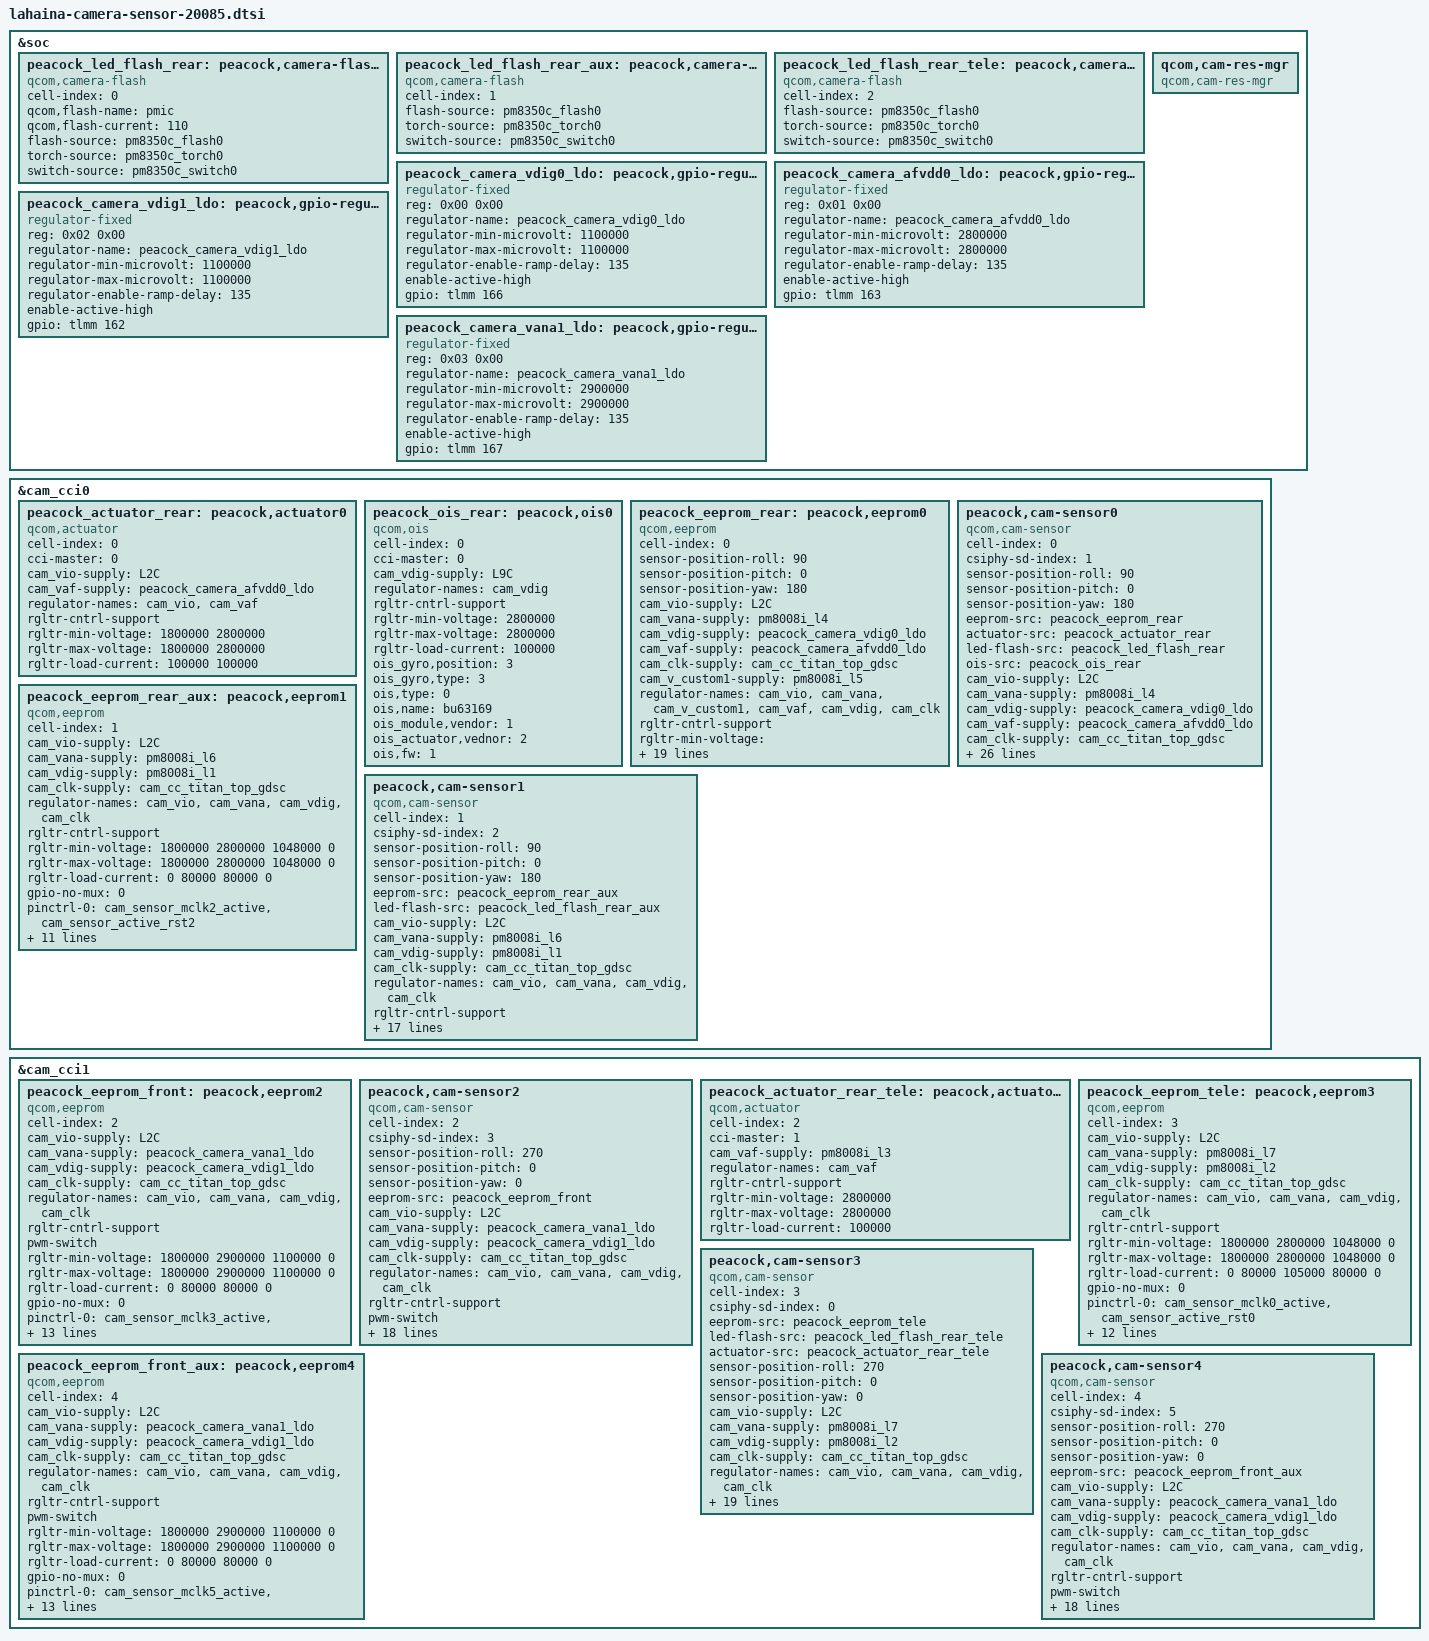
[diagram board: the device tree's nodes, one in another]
#include <dt-bindings/clock/qcom,camcc-lahaina.h>
&soc {
    peacock_led_flash_rear: peacock,camera-flash0 {
        cell-index = <0>;
        compatible = "qcom,camera-flash";
        qcom,flash-name = "pmic";
        qcom,flash-current = <110>;
        flash-source = <&pm8350c_flash0>;
        torch-source = <&pm8350c_torch0>;
        switch-source = <&pm8350c_switch0>;
        status = "ok";
    };

    peacock_led_flash_rear_aux: peacock,camera-flash1 {
        cell-index = <1>;
        compatible = "qcom,camera-flash";
        flash-source = <&pm8350c_flash0>;
        torch-source = <&pm8350c_torch0>;
        switch-source = <&pm8350c_switch0>;
        status = "ok";
    };

    peacock_led_flash_rear_tele: peacock,camera-flash2 {
        cell-index = <2>;
        compatible = "qcom,camera-flash";
        flash-source = <&pm8350c_flash0>;
        torch-source = <&pm8350c_torch0>;
        switch-source = <&pm8350c_switch0>;
        status = "ok";
    };

    peacock_camera_vdig0_ldo: peacock,gpio-regulator@0 {
        compatible = "regulator-fixed";
        reg = <0x00 0x00>;
        regulator-name = "peacock_camera_vdig0_ldo";
        regulator-min-microvolt = <1100000>;
        regulator-max-microvolt = <1100000>;
        regulator-enable-ramp-delay = <135>;
        enable-active-high;
        gpio = <&tlmm 166 0>;
        pinctrl-names = "default";
    };

    peacock_camera_afvdd0_ldo: peacock,gpio-regulator@1 {
        compatible = "regulator-fixed";
        reg = <0x01 0x00>;
        regulator-name = "peacock_camera_afvdd0_ldo";
        regulator-min-microvolt = <2800000>;
        regulator-max-microvolt = <2800000>;
        regulator-enable-ramp-delay = <135>;
        enable-active-high;
        gpio = <&tlmm 163 0>;
        pinctrl-names = "default";
    };

    peacock_camera_vdig1_ldo: peacock,gpio-regulator@2 {
        compatible = "regulator-fixed";
        reg = <0x02 0x00>;
        regulator-name = "peacock_camera_vdig1_ldo";
        regulator-min-microvolt = <1100000>;
        regulator-max-microvolt = <1100000>;
        regulator-enable-ramp-delay = <135>;
        enable-active-high;
        gpio = <&tlmm 162 0>;
        pinctrl-names = "default";
    };

    peacock_camera_vana1_ldo: peacock,gpio-regulator@3 {
        compatible = "regulator-fixed";
        reg = <0x03 0x00>;
        regulator-name = "peacock_camera_vana1_ldo";
        regulator-min-microvolt = <2900000>;
        regulator-max-microvolt = <2900000>;
        regulator-enable-ramp-delay = <135>;
        enable-active-high;
        gpio = <&tlmm 167 0>;
        pinctrl-names = "default";
    };

    qcom,cam-res-mgr {
        compatible = "qcom,cam-res-mgr";
        status = "ok";
    };
};

&cam_cci0 {
    peacock_actuator_rear: peacock,actuator0 {
        cell-index = <0>;
        compatible = "qcom,actuator";
        cci-master = <0>;
        cam_vio-supply = <&L2C>;
        cam_vaf-supply = <&peacock_camera_afvdd0_ldo>;
        regulator-names = "cam_vio", "cam_vaf";
        rgltr-cntrl-support;
        rgltr-min-voltage = <1800000 2800000>;
        rgltr-max-voltage = <1800000 2800000>;
        rgltr-load-current = <100000 100000>;
    };

    peacock_ois_rear: peacock,ois0 {
        cell-index = <0>;
        compatible = "qcom,ois";
        cci-master = <0>;
        cam_vdig-supply = <&L9C>;
        regulator-names = "cam_vdig";
        rgltr-cntrl-support;
        rgltr-min-voltage = <2800000>;
        rgltr-max-voltage = <2800000>;
        rgltr-load-current = <100000>;
        ois_gyro,position=<3>;
        ois_gyro,type=<3>;
        ois,type=<0>;
        ois,name="bu63169";
        ois_module,vendor=<1>;
        ois_actuator,vednor=<2>;
        ois,fw=<1>;
        status = "ok";
    };
    peacock_eeprom_rear: peacock,eeprom0 {
        cell-index = <0>;
        compatible = "qcom,eeprom";
        sensor-position-roll = <90>;
        sensor-position-pitch = <0>;
        sensor-position-yaw = <180>;
        cam_vio-supply = <&L2C>;
        cam_vana-supply = <&pm8008i_l4>;
        cam_vdig-supply = <&peacock_camera_vdig0_ldo>;
        cam_vaf-supply = <&peacock_camera_afvdd0_ldo>;
        cam_clk-supply = <&cam_cc_titan_top_gdsc>;
        cam_v_custom1-supply = <&pm8008i_l5>;
        regulator-names = "cam_vio", "cam_vana", "cam_v_custom1", "cam_vaf", "cam_vdig",
            "cam_clk";
        rgltr-cntrl-support;
        rgltr-min-voltage = <1800000 2800000 1800000 2800000 1100000 0>;
        rgltr-max-voltage = <1800000 2800000 1800000 2800000 1100000 0>;
        rgltr-load-current = <0 80000 80000 80000 105000 0>;
        gpio-no-mux = <0>;
        pinctrl-names = "cam_default", "cam_suspend";
        pinctrl-0 = <&cam_sensor_mclk1_active
                &cam_sensor_active_rst1>;
        pinctrl-1 = <&cam_sensor_mclk1_suspend
                &cam_sensor_suspend_rst1>;
        gpios = <&tlmm 101 0>,
            <&tlmm 16 0>;
        gpio-reset = <1>;
        gpio-req-tbl-num = <0 1>;
        gpio-req-tbl-flags = <1 0>;
        gpio-req-tbl-label = "CAMIF_MCLK1",
                    "CAM_RESET1";
        cci-master = <0>;
        status = "ok";
        clocks = <&clock_camcc CAM_CC_MCLK1_CLK>;
        clock-names = "cam_clk";
        clock-cntl-level = "nominal";
        clock-rates = <19200000>;
    };

    peacock,cam-sensor0 {
        cell-index = <0>;
        compatible = "qcom,cam-sensor";
        csiphy-sd-index = <1>;
        sensor-position-roll = <90>;
        sensor-position-pitch = <0>;
        sensor-position-yaw = <180>;
        eeprom-src = <&peacock_eeprom_rear>;
        actuator-src = <&peacock_actuator_rear>;
        led-flash-src = <&peacock_led_flash_rear>;
        ois-src = <&peacock_ois_rear>;
        cam_vio-supply = <&L2C>;
        cam_vana-supply = <&pm8008i_l4>;
        cam_vdig-supply = <&peacock_camera_vdig0_ldo>;
        cam_vaf-supply = <&peacock_camera_afvdd0_ldo>;
        cam_clk-supply = <&cam_cc_titan_top_gdsc>;
        cam_v_custom1-supply = <&pm8008i_l5>;
        regulator-names = "cam_vio", "cam_vana", "cam_v_custom1", "cam_vaf", "cam_vdig",
            "cam_clk";
        rgltr-cntrl-support;
        rgltr-min-voltage = <1800000 2800000 1800000 2800000 1100000 0>;
        rgltr-max-voltage = <1800000 2800000 1800000 2800000 1100000 0>;
        rgltr-load-current = <0 80000 80000 80000 105000 0>;
        gpio-no-mux = <0>;
        pinctrl-names = "cam_default", "cam_suspend";
        pinctrl-0 = <&cam_sensor_mclk1_active
                &cam_sensor_active_rst1>;
        pinctrl-1 = <&cam_sensor_mclk1_suspend
                &cam_sensor_suspend_rst1>;
        gpios = <&tlmm 101 0>,
            <&tlmm 16 0>;
        gpio-reset = <1>;
        gpio-req-tbl-num = <0 1>;
        gpio-req-tbl-flags = <1 0>;
        gpio-req-tbl-label = "CAMIF_MCLK1",
                    "CAM_RESET1";
        cci-master = <0>;
        status = "ok";
        clocks = <&clock_camcc CAM_CC_MCLK1_CLK>;
        clock-names = "cam_clk";
        clock-cntl-level = "nominal";
        clock-rates = <19200000>;
        is-read-eeprom = <2>;
        advance-powerup-vendor = <0x85>;
    };

    peacock_eeprom_rear_aux: peacock,eeprom1 {
        cell-index = <1>;
        compatible = "qcom,eeprom";
        cam_vio-supply = <&L2C>;
        cam_vana-supply = <&pm8008i_l6>;
        cam_vdig-supply = <&pm8008i_l1>;
        cam_clk-supply = <&cam_cc_titan_top_gdsc>;
        regulator-names = "cam_vio", "cam_vana", "cam_vdig", "cam_clk";
        rgltr-cntrl-support;
        rgltr-min-voltage = <1800000 2800000 1048000 0>;
        rgltr-max-voltage = <1800000 2800000 1048000 0>;
        rgltr-load-current = <0 80000 80000 0>;
        gpio-no-mux = <0>;
        pinctrl-names = "cam_default", "cam_suspend";
        pinctrl-0 = <&cam_sensor_mclk2_active
                &cam_sensor_active_rst2>;
        pinctrl-1 = <&cam_sensor_mclk2_suspend
                &cam_sensor_suspend_rst2>;
        gpios = <&tlmm 102 0>,
            <&tlmm 106 0>;
        gpio-reset = <1>;
        gpio-req-tbl-num = <0 1>;
        gpio-req-tbl-flags = <1 0>;
        gpio-req-tbl-label = "CAMIF_MCLK2",
                    "CAM_RESET2";
        cci-master = <1>;
        status = "ok";
        clocks = <&clock_camcc CAM_CC_MCLK2_CLK>;
        clock-names = "cam_clk";
        clock-cntl-level = "turbo";
        clock-rates = <19200000>;
    };

    peacock,cam-sensor1 {
        cell-index = <1>;
        compatible = "qcom,cam-sensor";
        csiphy-sd-index = <2>;
        sensor-position-roll = <90>;
        sensor-position-pitch = <0>;
        sensor-position-yaw = <180>;
        eeprom-src = <&peacock_eeprom_rear_aux>;
        led-flash-src = <&peacock_led_flash_rear_aux>;
        cam_vio-supply = <&L2C>;
        cam_vana-supply = <&pm8008i_l6>;
        cam_vdig-supply = <&pm8008i_l1>;
        cam_clk-supply = <&cam_cc_titan_top_gdsc>;
        regulator-names = "cam_vio", "cam_vana", "cam_vdig", "cam_clk";
        rgltr-cntrl-support;
        rgltr-min-voltage = <1800000 2800000 1048000 0>;
        rgltr-max-voltage = <1800000 2800000 1048000 0>;
        rgltr-load-current = <0 80000 80000 0>;
        gpio-no-mux = <0>;
        pinctrl-names = "cam_default", "cam_suspend";
        pinctrl-0 = <&cam_sensor_mclk2_active
                &cam_sensor_active_rst2>;
        pinctrl-1 = <&cam_sensor_mclk2_suspend
                &cam_sensor_suspend_rst2>;
        gpios = <&tlmm 102 0>,
            <&tlmm 106 0>;
        gpio-reset = <1>;
        gpio-req-tbl-num = <0 1>;
        gpio-req-tbl-flags = <1 0>;
        gpio-req-tbl-label = "CAMIF_MCLK2",
                    "CAM_RESET2";
        cci-master = <1>;
        status = "ok";
        clocks = <&clock_camcc CAM_CC_MCLK2_CLK>;
        clock-names = "cam_clk";
        clock-cntl-level = "turbo";
        clock-rates = <19200000>;
    };

};

&cam_cci1 {
    peacock_eeprom_front: peacock,eeprom2 {
        cell-index = <2>;
        compatible = "qcom,eeprom";
        cam_vio-supply = <&L2C>;
        cam_vana-supply = <&peacock_camera_vana1_ldo>;
        cam_vdig-supply = <&peacock_camera_vdig1_ldo>;
        cam_clk-supply = <&cam_cc_titan_top_gdsc>;
        regulator-names = "cam_vio", "cam_vana","cam_vdig",
            "cam_clk";
        rgltr-cntrl-support;
        pwm-switch;
        rgltr-min-voltage = <1800000 2900000 1100000 0>;
        rgltr-max-voltage = <1800000 2900000 1100000 0>;
        rgltr-load-current = <0 80000 80000 0>;
        gpio-no-mux = <0>;
        pinctrl-names = "cam_default", "cam_suspend";
        pinctrl-0 = <&cam_sensor_mclk3_active
                 &cam_sensor_active_rst5>;
        pinctrl-1 = <&cam_sensor_mclk3_suspend
                 &cam_sensor_suspend_rst5>;
        gpios = <&tlmm 103 0>,
            <&tlmm 115 0>;
        gpio-reset = <1>;
        gpio-req-tbl-num = <0 1>;
        gpio-req-tbl-flags = <1 0>;
        gpio-req-tbl-label = "CAMIF_MCLK3",
                    "CAM_RESET5";
        sensor-mode = <0>;
        cci-master = <0>;
        status = "ok";
        clocks = <&clock_camcc CAM_CC_MCLK3_CLK>;
        clock-names = "cam_clk";
        clock-cntl-level = "turbo";
        clock-rates = <19200000>;
    };

    peacock,cam-sensor2 {
        cell-index = <2>;
        compatible = "qcom,cam-sensor";
        csiphy-sd-index = <3>;
        sensor-position-roll = <270>;
        sensor-position-pitch = <0>;
        sensor-position-yaw = <0>;
        eeprom-src = <&peacock_eeprom_front>;
        cam_vio-supply = <&L2C>;
        cam_vana-supply = <&peacock_camera_vana1_ldo>;
        cam_vdig-supply = <&peacock_camera_vdig1_ldo>;
        cam_clk-supply = <&cam_cc_titan_top_gdsc>;
        regulator-names = "cam_vio", "cam_vana","cam_vdig",
            "cam_clk";
        rgltr-cntrl-support;
        pwm-switch;
        rgltr-min-voltage = <1800000 2900000 1100000 0>;
        rgltr-max-voltage = <1800000 2900000 1100000 0>;
        rgltr-load-current = <0 80000 80000 0>;
        gpio-no-mux = <0>;
        pinctrl-names = "cam_default", "cam_suspend";
        pinctrl-0 = <&cam_sensor_mclk3_active
                 &cam_sensor_active_rst5>;
        pinctrl-1 = <&cam_sensor_mclk3_suspend
                 &cam_sensor_suspend_rst5>;
        gpios = <&tlmm 103 0>,
            <&tlmm 115 0>;
        gpio-reset = <1>;
        gpio-req-tbl-num = <0 1>;
        gpio-req-tbl-flags = <1 0>;
        gpio-req-tbl-label = "CAMIF_MCLK3",
                    "CAM_RESET5";
        sensor-mode = <0>;
        cci-master = <0>;
        status = "ok";
        clocks = <&clock_camcc CAM_CC_MCLK3_CLK>;
        clock-names = "cam_clk";
        clock-cntl-level = "turbo";
        clock-rates = <19200000>;
    };

    peacock_actuator_rear_tele: peacock,actuator2 {
        cell-index = <2>;
        compatible = "qcom,actuator";
        cci-master = <1>;
        cam_vaf-supply = <&pm8008i_l3>;
        regulator-names = "cam_vaf";
        rgltr-cntrl-support;
        rgltr-min-voltage = <2800000>;
        rgltr-max-voltage = <2800000>;
        rgltr-load-current = <100000>;
    };

    peacock_eeprom_tele: peacock,eeprom3 {
        cell-index = <3>;
        compatible = "qcom,eeprom";
        cam_vio-supply = <&L2C>;
        cam_vana-supply = <&pm8008i_l7>;
        cam_vdig-supply = <&pm8008i_l2>;
        cam_clk-supply = <&cam_cc_titan_top_gdsc>;
        regulator-names = "cam_vio", "cam_vana", "cam_vdig",
            "cam_clk";
        rgltr-cntrl-support;
        rgltr-min-voltage = <1800000 2800000 1048000 0>;
        rgltr-max-voltage = <1800000 2800000 1048000 0>;
        rgltr-load-current = <0 80000 105000 80000 0>;
        gpio-no-mux = <0>;
        pinctrl-names = "cam_default", "cam_suspend";
        pinctrl-0 = <&cam_sensor_mclk0_active
                 &cam_sensor_active_rst0>;
        pinctrl-1 = <&cam_sensor_mclk0_suspend
                 &cam_sensor_suspend_rst0>;
        gpios = <&tlmm 100 0>,
            <&tlmm 17 0>;
        gpio-reset = <1>;
        gpio-req-tbl-num = <0 1>;
        gpio-req-tbl-flags = <1 0>;
        gpio-req-tbl-label = "CAMIF_MCLK0",
                    "CAM_RESET0";
        sensor-mode = <0>;
        cci-master = <1>;
        status = "ok";
        clocks = <&clock_camcc CAM_CC_MCLK0_CLK>;
        clock-names = "cam_clk";
        clock-cntl-level = "turbo";
        clock-rates = <19200000>;
    };

    peacock,cam-sensor3 {
        cell-index = <3>;
        compatible = "qcom,cam-sensor";
        csiphy-sd-index = <0>;
        eeprom-src = <&peacock_eeprom_tele>;
        led-flash-src = <&peacock_led_flash_rear_tele>;
        actuator-src = <&peacock_actuator_rear_tele>;
        sensor-position-roll = <270>;
        sensor-position-pitch = <0>;
        sensor-position-yaw = <0>;
        cam_vio-supply = <&L2C>;
        cam_vana-supply = <&pm8008i_l7>;
        cam_vdig-supply = <&pm8008i_l2>;
        cam_clk-supply = <&cam_cc_titan_top_gdsc>;
        regulator-names = "cam_vio", "cam_vana", "cam_vdig",
            "cam_clk";
        rgltr-cntrl-support;
        rgltr-min-voltage = <1800000 2800000 1048000 0>;
        rgltr-max-voltage = <1800000 2800000 1048000 0>;
        rgltr-load-current = <0 80000 105000 80000 0>;
        gpio-no-mux = <0>;
        pinctrl-names = "cam_default", "cam_suspend";
        pinctrl-0 = <&cam_sensor_mclk0_active
                 &cam_sensor_active_rst0>;
        pinctrl-1 = <&cam_sensor_mclk0_suspend
                 &cam_sensor_suspend_rst0>;
        gpios = <&tlmm 100 0>,
            <&tlmm 17 0>;
        gpio-reset = <1>;
        gpio-req-tbl-num = <0 1>;
        gpio-req-tbl-flags = <1 0>;
        gpio-req-tbl-label = "CAMIF_MCLK0",
                    "CAM_RESET0";
        sensor-mode = <0>;
        cci-master = <1>;
        status = "ok";
        clocks = <&clock_camcc CAM_CC_MCLK0_CLK>;
        clock-names = "cam_clk";
        clock-cntl-level = "turbo";
        clock-rates = <19200000>;
    };

    peacock_eeprom_front_aux: peacock,eeprom4 {
        cell-index = <4>;
        compatible = "qcom,eeprom";
        cam_vio-supply = <&L2C>;
        cam_vana-supply = <&peacock_camera_vana1_ldo>;
        cam_vdig-supply = <&peacock_camera_vdig1_ldo>;
        cam_clk-supply = <&cam_cc_titan_top_gdsc>;
        regulator-names = "cam_vio", "cam_vana","cam_vdig",
            "cam_clk";
        rgltr-cntrl-support;
        pwm-switch;
        rgltr-min-voltage = <1800000 2900000 1100000 0>;
        rgltr-max-voltage = <1800000 2900000 1100000 0>;
        rgltr-load-current = <0 80000 80000 0>;
        gpio-no-mux = <0>;
        pinctrl-names = "cam_default", "cam_suspend";
        pinctrl-0 = <&cam_sensor_mclk5_active
                 &cam_sensor_active_rst3>;
        pinctrl-1 = <&cam_sensor_mclk5_suspend
                 &cam_sensor_suspend_rst3>;
        gpios = <&tlmm 105 0>,
            <&tlmm 117 0>;
        gpio-reset = <1>;
        gpio-req-tbl-num = <0 1>;
        gpio-req-tbl-flags = <1 0>;
        gpio-req-tbl-label = "CAMIF_MCLK5",
                    "CAM_RESET3";
        sensor-mode = <0>;
        cci-master = <1>;
        status = "ok";
        clocks = <&clock_camcc CAM_CC_MCLK5_CLK>;
        clock-names = "cam_clk";
        clock-cntl-level = "turbo";
        clock-rates = <19200000>;
    };

    peacock,cam-sensor4 {
        cell-index = <4>;
        compatible = "qcom,cam-sensor";
        csiphy-sd-index = <5>;
        sensor-position-roll = <270>;
        sensor-position-pitch = <0>;
        sensor-position-yaw = <0>;
        eeprom-src = <&peacock_eeprom_front_aux>;
        cam_vio-supply = <&L2C>;
        cam_vana-supply = <&peacock_camera_vana1_ldo>;
        cam_vdig-supply = <&peacock_camera_vdig1_ldo>;
        cam_clk-supply = <&cam_cc_titan_top_gdsc>;
        regulator-names = "cam_vio", "cam_vana","cam_vdig",
            "cam_clk";
        rgltr-cntrl-support;
        pwm-switch;
        rgltr-min-voltage = <1800000 2900000 1100000 0>;
        rgltr-max-voltage = <1800000 2900000 1100000 0>;
        rgltr-load-current = <0 80000 80000 0>;
        gpio-no-mux = <0>;
        pinctrl-names = "cam_default", "cam_suspend";
        pinctrl-0 = <&cam_sensor_mclk5_active
                 &cam_sensor_active_rst3>;
        pinctrl-1 = <&cam_sensor_mclk5_suspend
                 &cam_sensor_suspend_rst3>;
        gpios = <&tlmm 105 0>,
            <&tlmm 117 0>;
        gpio-reset = <1>;
        gpio-req-tbl-num = <0 1>;
        gpio-req-tbl-flags = <1 0>;
        gpio-req-tbl-label = "CAMIF_MCLK5",
                    "CAM_RESET3";
        sensor-mode = <0>;
        cci-master = <1>;
        status = "ok";
        clocks = <&clock_camcc CAM_CC_MCLK5_CLK>;
        clock-names = "cam_clk";
        clock-cntl-level = "turbo";
        clock-rates = <19200000>;
    };
};
